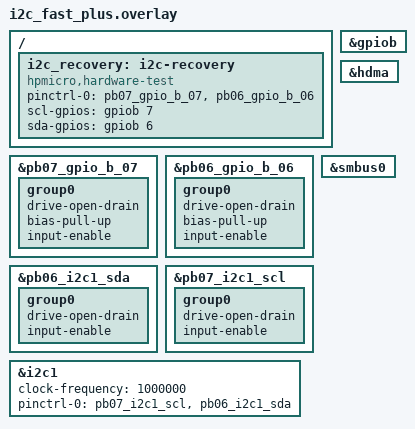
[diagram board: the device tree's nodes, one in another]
/* SPDX-License-Identifier: Apache-2.0 */

/ {
	i2c_recovery: i2c-recovery {
		compatible = "hpmicro,hardware-test";
		pinctrl-0 = <&pb07_gpio_b_07 &pb06_gpio_b_06>;
		pinctrl-names = "default";
		scl-gpios = <&gpiob 7 GPIO_ACTIVE_HIGH>;
		sda-gpios = <&gpiob 6 GPIO_ACTIVE_HIGH>;
	};
};

&gpiob {
	status = "okay";
};

&pb07_gpio_b_07 {
	group0 {
		drive-open-drain;
		bias-pull-up;
		input-enable;
	};
};

&pb06_gpio_b_06 {
	group0 {
		drive-open-drain;
		bias-pull-up;
		input-enable;
	};
};

&pb06_i2c1_sda {
	group0 {
		drive-open-drain;
		input-enable;
	};
};

&pb07_i2c1_scl {
	group0 {
		drive-open-drain;
		input-enable;
	};
};

&i2c1 {
	status = "okay";
	clock-frequency = <1000000>;
	pinctrl-0 = <&pb07_i2c1_scl &pb06_i2c1_sda>;
	pinctrl-names = "default";
};

&hdma {
	status = "okay";
};

&smbus0 {
	status = "okay";
};
